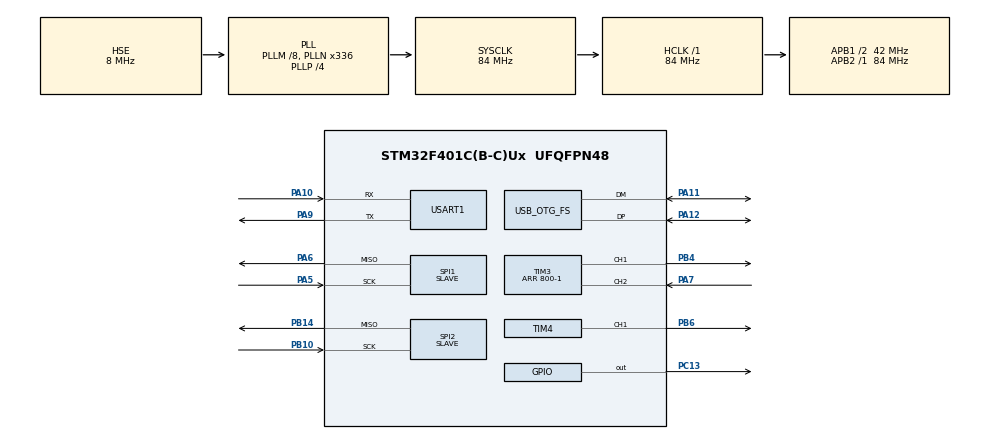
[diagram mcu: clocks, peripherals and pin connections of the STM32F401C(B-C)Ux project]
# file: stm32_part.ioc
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Dma.Request0=SPI1_TX
Dma.Request1=SPI2_TX
Dma.SPI1_TX.0.Direction=DMA_MEMORY_TO_PERIPH
Dma.SPI1_TX.0.FIFOMode=DMA_FIFOMODE_DISABLE
Dma.SPI1_TX.0.Instance=DMA2_Stream3
Dma.SPI1_TX.0.MemDataAlignment=DMA_MDATAALIGN_BYTE
Dma.SPI1_TX.0.MemInc=DMA_MINC_ENABLE
Dma.SPI1_TX.0.Mode=DMA_CIRCULAR
Dma.SPI1_TX.0.PeriphDataAlignment=DMA_PDATAALIGN_BYTE
Dma.SPI1_TX.0.PeriphInc=DMA_PINC_DISABLE
Dma.SPI1_TX.0.Priority=DMA_PRIORITY_VERY_HIGH
Dma.SPI2_TX.1.Direction=DMA_MEMORY_TO_PERIPH
Dma.SPI2_TX.1.FIFOMode=DMA_FIFOMODE_DISABLE
Dma.SPI2_TX.1.Instance=DMA1_Stream4
Dma.SPI2_TX.1.MemDataAlignment=DMA_MDATAALIGN_BYTE
Dma.SPI2_TX.1.MemInc=DMA_MINC_ENABLE
Dma.SPI2_TX.1.Mode=DMA_CIRCULAR
Dma.SPI2_TX.1.PeriphDataAlignment=DMA_PDATAALIGN_BYTE
Dma.SPI2_TX.1.PeriphInc=DMA_PINC_DISABLE
Dma.SPI2_TX.1.Priority=DMA_PRIORITY_HIGH
Mcu.Family=STM32F4
Mcu.Name=STM32F401C(B-C)Ux
Mcu.Package=UFQFPN48
NVIC.DMA1_Stream4_IRQn=true\:0\:0\:false\:false\:true\:false\:true
NVIC.DMA2_Stream3_IRQn=true\:0\:0\:false\:false\:true\:false\:true
NVIC.PriorityGroup=NVIC_PRIORITYGROUP_4
NVIC.TIM3_IRQn=true\:0\:0\:false\:false\:true\:true\:true
NVIC.TIM4_IRQn=true\:0\:0\:false\:false\:true\:true\:true
PA10.Mode=Asynchronous
PA10.Signal=USART1_RX
PA11.Mode=Host_Only
PA11.Signal=USB_OTG_FS_DM
PA12.Mode=Host_Only
PA12.Signal=USB_OTG_FS_DP
PA5.Mode=TX_Only_Simplex_Unidirect_Slave
PA5.Signal=SPI1_SCK
PA6.Mode=TX_Only_Simplex_Unidirect_Slave
PA6.Signal=SPI1_MISO
PA7.Signal=S_TIM3_CH2
PA9.Mode=Asynchronous
PA9.Signal=USART1_TX
PB10.Mode=TX_Only_Simplex_Unidirect_Slave
PB10.Signal=SPI2_SCK
PB14.Mode=TX_Only_Simplex_Unidirect_Slave
PB14.Signal=SPI2_MISO
PB4.Signal=S_TIM3_CH1
PB6.Signal=S_TIM4_CH1
PC13-ANTI_TAMP.Signal=GPIO_Output
PH0\ -\ OSC_IN.Mode=HSE-External-Oscillator
PH0\ -\ OSC_IN.Signal=RCC_OSC_IN
PH1\ -\ OSC_OUT.Mode=HSE-External-Oscillator
PH1\ -\ OSC_OUT.Signal=RCC_OSC_OUT
ProjectManager.HeapSize=0x200
ProjectManager.StackSize=0x400
ProjectManager.TargetToolchain=STM32CubeIDE
RCC.48MHZClocksFreq_Value=48000000
RCC.AHBFreq_Value=84000000
RCC.APB1CLKDivider=RCC_HCLK_DIV2
RCC.APB1Freq_Value=42000000
RCC.APB1TimFreq_Value=84000000
RCC.APB2Freq_Value=84000000
RCC.APB2TimFreq_Value=84000000
RCC.CortexFreq_Value=84000000
RCC.HCLKFreq_Value=84000000
RCC.HSE_VALUE=8000000
RCC.HSI_VALUE=16000000
RCC.LSE_VALUE=32768
RCC.PLLM=8
RCC.PLLN=336
RCC.PLLP=RCC_PLLP_DIV4
RCC.PLLQ=7
RCC.SYSCLKFreq_VALUE=84000000
RCC.SYSCLKSource=RCC_SYSCLKSOURCE_PLLCLK
RCC.VCOOutputFreq_Value=336000000
SH.S_TIM3_CH1.0=TIM3_CH1,PWM Generation1 CH1
SH.S_TIM3_CH2.0=TIM3_CH2,TriggerSource_TI2FP2
SH.S_TIM4_CH1.0=TIM4_CH1,PWM Generation1 CH1
SPI1.Direction=SPI_DIRECTION_2LINES
SPI1.Mode=SPI_MODE_SLAVE
SPI1.VirtualType=VM_SLAVE
SPI2.Direction=SPI_DIRECTION_2LINES
SPI2.Mode=SPI_MODE_SLAVE
SPI2.VirtualType=VM_SLAVE
TIM3.Channel-Output\ Compare3\ No\ Output=TIM_CHANNEL_3
TIM3.Channel-PWM\ Generation1\ CH1=TIM_CHANNEL_1
TIM3.Period=800-1
TIM3.Pulse-Output\ Compare3\ No\ Output=790
TIM3.Pulse-PWM\ Generation1\ CH1=20
TIM3.TIM_MasterOutputTrigger=TIM_TRGO_UPDATE
TIM3.TIM_MasterSlaveMode=TIM_MASTERSLAVEMODE_ENABLE
TIM4.Channel-Output\ Compare2\ No\ Output=TIM_CHANNEL_2
TIM4.Channel-Output\ Compare3\ No\ Output=TIM_CHANNEL_3
TIM4.Channel-Output\ Compare4\ No\ Output=TIM_CHANNEL_4
TIM4.Channel-PWM\ Generation1\ CH1=TIM_CHANNEL_1
TIM4.Period=525-1
TIM4.Pulse-Output\ Compare2\ No\ Output=22
TIM4.Pulse-Output\ Compare4\ No\ Output=21
TIM4.Pulse-PWM\ Generation1\ CH1=50
USART1.VirtualMode=VM_ASYNC
USB_OTG_FS.VirtualMode=Host_Only
USB_OTG_FS.phy_itface=HCD_PHY_EMBEDDED
VP_TIM3_VS_ControllerModeClock.Mode=Clock Mode
VP_TIM3_VS_no_output3.Mode=Output Compare3 No Output
VP_TIM4_VS_ClockSourceITR.Mode=TriggerSource_ITR2
VP_TIM4_VS_ControllerModeClock.Mode=Clock Mode
VP_TIM4_VS_no_output2.Mode=Output Compare2 No Output
VP_TIM4_VS_no_output3.Mode=Output Compare3 No Output
VP_TIM4_VS_no_output4.Mode=Output Compare4 No Output
board=custom

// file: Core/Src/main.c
/* USER CODE BEGIN Header */
/**
  ******************************************************************************
  * @file           : main.c
  * @brief          : Main program body
  ******************************************************************************
  * @attention
  *
  * <h2><center>&copy; Copyright (c) 2021 STMicroelectronics.
  * All rights reserved.</center></h2>
  *
  * This software component is licensed by ST under BSD 3-Clause license,
  * the "License"; You may not use this file except in compliance with the
  * License. You may obtain a copy of the License at:
  *                        opensource.org/licenses/BSD-3-Clause
  *
  ******************************************************************************
  */
/* USER CODE END Header */
#include "main.h"
#include "dma.h"
#include "spi.h"
#include "tim.h"
#include "usart.h"
#include "usb_otg.h"
#include "gpio.h"

/* USER CODE BEGIN PV */
uint8_t screen[60][100];

/* USER CODE END PV */

void SystemClock_Config(void);

int main(void)
{

  /* MCU Configuration--------------------------------------------------------*/

  /* Reset of all peripherals, Initializes the Flash interface and the Systick. */
  HAL_Init();

  /* Configure the system clock */
  SystemClock_Config();

  /* USER CODE BEGIN SysInit */
  for(uint8_t x = 0; x < 60; x++){

	  for(uint8_t y = 9; y < 89; y++){
		  screen[x][y] = 66;
	  }
  }

  /* USER CODE END SysInit */

  /* Initialize all configured peripherals */
  MX_GPIO_Init();
  MX_DMA_Init();
  MX_SPI1_Init();
  MX_SPI2_Init();
  MX_TIM3_Init();
  MX_TIM4_Init();
  MX_USART1_UART_Init();
  MX_USB_OTG_FS_HCD_Init();
  /* USER CODE BEGIN 2 */

  HAL_TIM_PWM_Start(&htim3, TIM_CHANNEL_1);
  HAL_TIM_PWM_Start(&htim4, TIM_CHANNEL_1);
  HAL_TIM_OC_Start_IT(&htim3, TIM_CHANNEL_3);
  HAL_TIM_OC_Start_IT(&htim4, TIM_CHANNEL_2);
  HAL_TIM_OC_Start_IT(&htim4, TIM_CHANNEL_3);
  HAL_TIM_OC_Start_IT(&htim4, TIM_CHANNEL_4);

  //HAL_GPIO_WritePin(GPIOC, GPIO_PIN_13, GPIO_PIN_SET);
  /* USER CODE END 2 */

  /* Infinite loop */
  while (1)
  {

  }
}

void SystemClock_Config(void)
{
  RCC_OscInitTypeDef RCC_OscInitStruct = {0};
  RCC_ClkInitTypeDef RCC_ClkInitStruct = {0};

  /** Configure the main internal regulator output voltage
  */
  __HAL_RCC_PWR_CLK_ENABLE();
  __HAL_PWR_VOLTAGESCALING_CONFIG(PWR_REGULATOR_VOLTAGE_SCALE2);
  /** Initializes the RCC Oscillators according to the specified parameters
  * in the RCC_OscInitTypeDef structure.
  */
  RCC_OscInitStruct.OscillatorType = RCC_OSCILLATORTYPE_HSE;
  RCC_OscInitStruct.HSEState = RCC_HSE_ON;
  RCC_OscInitStruct.PLL.PLLState = RCC_PLL_ON;
  RCC_OscInitStruct.PLL.PLLSource = RCC_PLLSOURCE_HSE;
  RCC_OscInitStruct.PLL.PLLM = 8;
  RCC_OscInitStruct.PLL.PLLN = 336;
  RCC_OscInitStruct.PLL.PLLP = RCC_PLLP_DIV4;
  RCC_OscInitStruct.PLL.PLLQ = 7;
  if (HAL_RCC_OscConfig(&RCC_OscInitStruct) != HAL_OK)
  {
    Error_Handler();
  }
  /** Initializes the CPU, AHB and APB buses clocks
  */
  RCC_ClkInitStruct.ClockType = RCC_CLOCKTYPE_HCLK|RCC_CLOCKTYPE_SYSCLK
                              |RCC_CLOCKTYPE_PCLK1|RCC_CLOCKTYPE_PCLK2;
  RCC_ClkInitStruct.SYSCLKSource = RCC_SYSCLKSOURCE_PLLCLK;
  RCC_ClkInitStruct.AHBCLKDivider = RCC_SYSCLK_DIV1;
  RCC_ClkInitStruct.APB1CLKDivider = RCC_HCLK_DIV2;
  RCC_ClkInitStruct.APB2CLKDivider = RCC_HCLK_DIV1;

  if (HAL_RCC_ClockConfig(&RCC_ClkInitStruct, FLASH_LATENCY_2) != HAL_OK)
  {
    Error_Handler();
  }
}

void Error_Handler(void)
{
  __disable_irq();
  while (1)
  {
  }
}

/************************ (C) COPYRIGHT STMicroelectronics *****END OF FILE****/
